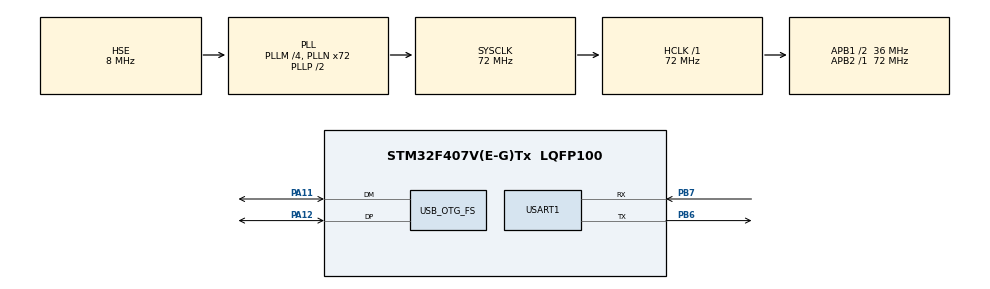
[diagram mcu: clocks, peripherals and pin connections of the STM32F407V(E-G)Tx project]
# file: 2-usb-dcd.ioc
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Mcu.Family=STM32F4
Mcu.Name=STM32F407V(E-G)Tx
Mcu.Package=LQFP100
NVIC.OTG_FS_IRQn=true\:0\:0\:false\:false\:true\:true\:true\:true
NVIC.PriorityGroup=NVIC_PRIORITYGROUP_4
NVIC.USART1_IRQn=true\:0\:0\:false\:false\:true\:true\:true\:true
PA11.Mode=Device_Only
PA11.Signal=USB_OTG_FS_DM
PA12.Mode=Device_Only
PA12.Signal=USB_OTG_FS_DP
PA13.Mode=Serial_Wire
PA13.Signal=SYS_JTMS-SWDIO
PA14.Mode=Serial_Wire
PA14.Signal=SYS_JTCK-SWCLK
PB6.Mode=Asynchronous
PB6.Signal=USART1_TX
PB7.Mode=Asynchronous
PB7.Signal=USART1_RX
PH0-OSC_IN.Mode=HSE-External-Oscillator
PH0-OSC_IN.Signal=RCC_OSC_IN
PH1-OSC_OUT.Mode=HSE-External-Oscillator
PH1-OSC_OUT.Signal=RCC_OSC_OUT
ProjectManager.HeapSize=0x600
ProjectManager.StackSize=0x600
ProjectManager.TargetToolchain=MDK-ARM V5.32
RCC.48MHZClocksFreq_Value=48000000
RCC.AHBFreq_Value=72000000
RCC.APB1CLKDivider=RCC_HCLK_DIV2
RCC.APB1Freq_Value=36000000
RCC.APB1TimFreq_Value=72000000
RCC.APB2Freq_Value=72000000
RCC.APB2TimFreq_Value=72000000
RCC.CortexFreq_Value=72000000
RCC.HCLKFreq_Value=72000000
RCC.HSE_VALUE=8000000
RCC.HSI_VALUE=16000000
RCC.LSE_VALUE=32768
RCC.PLLM=4
RCC.PLLN=72
RCC.PLLQ=3
RCC.SYSCLKFreq_VALUE=72000000
RCC.SYSCLKSource=RCC_SYSCLKSOURCE_PLLCLK
RCC.VCOOutputFreq_Value=144000000
USART1.VirtualMode=VM_ASYNC
USB_DEVICE.CLASS_NAME_FS=CDC
USB_DEVICE.VirtualMode-CDC_FS=Cdc
USB_DEVICE.VirtualModeFS=Cdc_FS
USB_OTG_FS.VirtualMode=Device_Only
VP_USB_DEVICE_VS_USB_DEVICE_CDC_FS.Mode=CDC_FS
board=custom

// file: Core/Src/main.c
/* USER CODE BEGIN Header */
/**
  ******************************************************************************
  * @file           : main.c
  * @brief          : Main program body
  ******************************************************************************
  * @attention
  *
  * Copyright (c) 2026 STMicroelectronics.
  * All rights reserved.
  *
  * This software is licensed under terms that can be found in the LICENSE file
  * in the root directory of this software component.
  * If no LICENSE file comes with this software, it is provided AS-IS.
  *
  ******************************************************************************
  */
/* USER CODE END Header */
#include "main.h"
#include "usb_device.h"

/* USER CODE BEGIN Includes */
#include "uart_usb_bridge.h"

/* USER CODE END Includes */

UART_HandleTypeDef huart1;

void SystemClock_Config(void);
static void MX_GPIO_Init(void);
static void MX_USART1_UART_Init(void);

int main(void)
{

  /* MCU Configuration--------------------------------------------------------*/

  /* Reset of all peripherals, Initializes the Flash interface and the Systick. */
  HAL_Init();

  /* Configure the system clock */
  SystemClock_Config();

  /* Initialize all configured peripherals */
  MX_GPIO_Init();
  MX_USB_DEVICE_Init();
  MX_USART1_UART_Init();

  /* Infinite loop */
  while (1)
  {

    /* USER CODE BEGIN 3 */
		USB_Bridge();
  }
  /* USER CODE END 3 */
}

void SystemClock_Config(void)
{
  RCC_OscInitTypeDef RCC_OscInitStruct = {0};
  RCC_ClkInitTypeDef RCC_ClkInitStruct = {0};

  /** Configure the main internal regulator output voltage
  */
  __HAL_RCC_PWR_CLK_ENABLE();
  __HAL_PWR_VOLTAGESCALING_CONFIG(PWR_REGULATOR_VOLTAGE_SCALE1);

  /** Initializes the RCC Oscillators according to the specified parameters
  * in the RCC_OscInitTypeDef structure.
  */
  RCC_OscInitStruct.OscillatorType = RCC_OSCILLATORTYPE_HSE;
  RCC_OscInitStruct.HSEState = RCC_HSE_ON;
  RCC_OscInitStruct.PLL.PLLState = RCC_PLL_ON;
  RCC_OscInitStruct.PLL.PLLSource = RCC_PLLSOURCE_HSE;
  RCC_OscInitStruct.PLL.PLLM = 4;
  RCC_OscInitStruct.PLL.PLLN = 72;
  RCC_OscInitStruct.PLL.PLLP = RCC_PLLP_DIV2;
  RCC_OscInitStruct.PLL.PLLQ = 3;
  if (HAL_RCC_OscConfig(&RCC_OscInitStruct) != HAL_OK)
  {
    Error_Handler();
  }

  /** Initializes the CPU, AHB and APB buses clocks
  */
  RCC_ClkInitStruct.ClockType = RCC_CLOCKTYPE_HCLK|RCC_CLOCKTYPE_SYSCLK
                              |RCC_CLOCKTYPE_PCLK1|RCC_CLOCKTYPE_PCLK2;
  RCC_ClkInitStruct.SYSCLKSource = RCC_SYSCLKSOURCE_PLLCLK;
  RCC_ClkInitStruct.AHBCLKDivider = RCC_SYSCLK_DIV1;
  RCC_ClkInitStruct.APB1CLKDivider = RCC_HCLK_DIV2;
  RCC_ClkInitStruct.APB2CLKDivider = RCC_HCLK_DIV1;

  if (HAL_RCC_ClockConfig(&RCC_ClkInitStruct, FLASH_LATENCY_2) != HAL_OK)
  {
    Error_Handler();
  }
}

static void MX_USART1_UART_Init(void)
{

  huart1.Instance = USART1;
  huart1.Init.BaudRate = 115200;
  huart1.Init.WordLength = UART_WORDLENGTH_8B;
  huart1.Init.StopBits = UART_STOPBITS_1;
  huart1.Init.Parity = UART_PARITY_NONE;
  huart1.Init.Mode = UART_MODE_TX_RX;
  huart1.Init.HwFlowCtl = UART_HWCONTROL_NONE;
  huart1.Init.OverSampling = UART_OVERSAMPLING_16;
  if (HAL_UART_Init(&huart1) != HAL_OK)
  {
    Error_Handler();
  }

}

static void MX_GPIO_Init(void)
{
  GPIO_InitTypeDef GPIO_InitStruct = {0};

  /* GPIO Ports Clock Enable */
  __HAL_RCC_GPIOE_CLK_ENABLE();
  __HAL_RCC_GPIOC_CLK_ENABLE();
  __HAL_RCC_GPIOH_CLK_ENABLE();
  __HAL_RCC_GPIOA_CLK_ENABLE();
  __HAL_RCC_GPIOB_CLK_ENABLE();
  __HAL_RCC_GPIOD_CLK_ENABLE();

  /*Configure GPIO pins : PE2 PE3 PE4 PE5
                           PE6 PE7 PE8 PE9
                           PE10 PE11 PE12 PE13
                           PE14 PE15 PE0 PE1 */
  GPIO_InitStruct.Pin = GPIO_PIN_2|GPIO_PIN_3|GPIO_PIN_4|GPIO_PIN_5
                          |GPIO_PIN_6|GPIO_PIN_7|GPIO_PIN_8|GPIO_PIN_9
                          |GPIO_PIN_10|GPIO_PIN_11|GPIO_PIN_12|GPIO_PIN_13
                          |GPIO_PIN_14|GPIO_PIN_15|GPIO_PIN_0|GPIO_PIN_1;
  GPIO_InitStruct.Mode = GPIO_MODE_ANALOG;
  GPIO_InitStruct.Pull = GPIO_NOPULL;
  HAL_GPIO_Init(GPIOE, &GPIO_InitStruct);

  /*Configure GPIO pins : PC13 PC14 PC15 PC0
                           PC1 PC2 PC3 PC4
                           PC5 PC6 PC7 PC8
                           PC9 PC10 PC11 PC12 */
  GPIO_InitStruct.Pin = GPIO_PIN_13|GPIO_PIN_14|GPIO_PIN_15|GPIO_PIN_0
                          |GPIO_PIN_1|GPIO_PIN_2|GPIO_PIN_3|GPIO_PIN_4
                          |GPIO_PIN_5|GPIO_PIN_6|GPIO_PIN_7|GPIO_PIN_8
                          |GPIO_PIN_9|GPIO_PIN_10|GPIO_PIN_11|GPIO_PIN_12;
  GPIO_InitStruct.Mode = GPIO_MODE_ANALOG;
  GPIO_InitStruct.Pull = GPIO_NOPULL;
  HAL_GPIO_Init(GPIOC, &GPIO_InitStruct);

  /*Configure GPIO pins : PA0 PA1 PA2 PA3
                           PA4 PA5 PA6 PA7
                           PA8 PA9 PA10 PA15 */
  GPIO_InitStruct.Pin = GPIO_PIN_0|GPIO_PIN_1|GPIO_PIN_2|GPIO_PIN_3
                          |GPIO_PIN_4|GPIO_PIN_5|GPIO_PIN_6|GPIO_PIN_7
                          |GPIO_PIN_8|GPIO_PIN_9|GPIO_PIN_10|GPIO_PIN_15;
  GPIO_InitStruct.Mode = GPIO_MODE_ANALOG;
  GPIO_InitStruct.Pull = GPIO_NOPULL;
  HAL_GPIO_Init(GPIOA, &GPIO_InitStruct);

  /*Configure GPIO pins : PB0 PB1 PB2 PB10
                           PB11 PB12 PB13 PB14
                           PB15 PB3 PB4 PB5
                           PB8 PB9 */
  GPIO_InitStruct.Pin = GPIO_PIN_0|GPIO_PIN_1|GPIO_PIN_2|GPIO_PIN_10
                          |GPIO_PIN_11|GPIO_PIN_12|GPIO_PIN_13|GPIO_PIN_14
                          |GPIO_PIN_15|GPIO_PIN_3|GPIO_PIN_4|GPIO_PIN_5
                          |GPIO_PIN_8|GPIO_PIN_9;
  GPIO_InitStruct.Mode = GPIO_MODE_ANALOG;
  GPIO_InitStruct.Pull = GPIO_NOPULL;
  HAL_GPIO_Init(GPIOB, &GPIO_InitStruct);

  /*Configure GPIO pins : PD8 PD9 PD10 PD11
                           PD12 PD13 PD14 PD15
                           PD0 PD1 PD2 PD3
                           PD4 PD5 PD6 PD7 */
  GPIO_InitStruct.Pin = GPIO_PIN_8|GPIO_PIN_9|GPIO_PIN_10|GPIO_PIN_11
                          |GPIO_PIN_12|GPIO_PIN_13|GPIO_PIN_14|GPIO_PIN_15
                          |GPIO_PIN_0|GPIO_PIN_1|GPIO_PIN_2|GPIO_PIN_3
                          |GPIO_PIN_4|GPIO_PIN_5|GPIO_PIN_6|GPIO_PIN_7;
  GPIO_InitStruct.Mode = GPIO_MODE_ANALOG;
  GPIO_InitStruct.Pull = GPIO_NOPULL;
  HAL_GPIO_Init(GPIOD, &GPIO_InitStruct);

}

void Error_Handler(void)
{
  __disable_irq();
  while (1)
  {
  }
}
